# M2354 register map
File version: 1.0
Registers are 32-bit, read-write, reset 0x0 unless marked. A register's access mark holds for its fields unless they carry their own. Offsets are from the block's base; [hi:lo] are bit positions; {n}, {i} and the like mark numbered series; 'fields as' and 'values as' point back to an identical list.

## ECC_NS — CRYPTO Register Map
Base 0x50032800
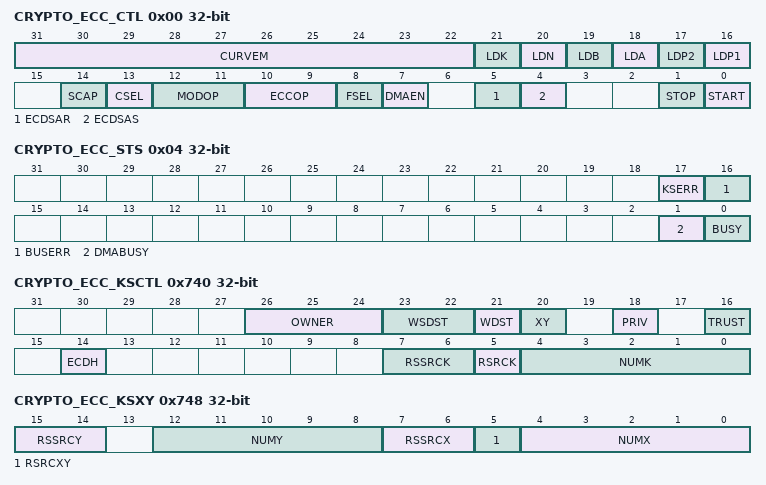
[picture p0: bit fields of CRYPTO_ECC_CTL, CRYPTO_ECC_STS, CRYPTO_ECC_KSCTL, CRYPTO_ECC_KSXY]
0x00 CRYPTO_ECC_CTL — ECC Control Register
  [31:22] CURVEM — The key length of elliptic curve.
  [21] LDK — The Control Signal of Register for SCALARK
    0=The register for SCALARK is not modified by DMA or user; 1=The register for SCALARK is modified by DMA or user
  [20] LDN — The Control Signal of Register for the Parameter CURVEN of Elliptic Curve
    0=The register for CURVEN is not modified by DMA or user; 1=The register for CURVEN is modified by DMA or user
  [19] LDB — The Control Signal of Register for the Parameter CURVEB of Elliptic Curve
    0=The register for CURVEB is not modified by DMA or user; 1=The register for CURVEB is modified by DMA or user
  [18] LDA — The Control Signal of Register for the Parameter CURVEA of Elliptic Curve
    0=The register for CURVEA is not modified by DMA or user; 1=The register for CURVEA is modified by DMA or user
  [17] LDP2 — The Control Signal of Register POINTX2 and POINTY2 for the x and Y Coordinate of the Second Point
    0=The register for POINTX2 and POINTY2 is not modified by DMA or user; 1=The register for POINTX2 and POINTY2 is modified by DMA or user
  [16] LDP1 — The Control Signal of Register POINTX1 and POINTY1 for the x and Y Coordinate of the First Point
    0=The register for POINTX1 and POINTY1 is not modified by DMA or user; 1=The register for POINTX1 and POINTY1 is modified by DMA or user
  [14] SCAP — Side-channel Attack Protection
    0=Full speed without side-channel protection; 1=Less speed with side-channel protection
  [13] CSEL — Curve Selection
    0=NIST suggested curve; 1=Montgomery curve
  [12:11] MODOP — Modulus Operation for PF
    0=Division; 1=Multiplication :; 2=Addition; 3=Subtraction :
  [10:9] ECCOP — Point Operation for BF and PF. Besides above three input data, point operations still need the parameters of elliptic curve (CURVEA, CURVEB, CURVEN and CURVEM) as shown in Figure 6.27-11.
    0=Point multiplication; 1=Modulus operation : choose by MODOP (CRYPTO_ECC_CTL[12:11]); 2=Point addition; 3=Point doubling
  [8] FSEL — Field Selection
    0=Binary Field (GF(2m )); 1=Prime Field (GF(p))
  [7] DMAEN — ECC Accelerator DMA Enable Bit. Note: Only when START and DMAEN are 1, ECC DMA engine will be active.
    0=ECC DMA engine Disabled; 1=ECC DMA engine Enabled
  [5] ECDSAR — Generate R in ECDSA Signature Generation
    0=No effect; 1=Formula for generating R
  [4] ECDSAS — Generate S in ECDSA Signature Generation
    0=No effect; 1=Formula for generating S
  [1] STOP — ECC Accelerator Stop. Note: This bit is always 0 when it is read back. Remember to clear ECC interrupt flag after stopping ECC accelerator.
    0=No effect; 1=Abort ECC accelerator and make it into idle state
  [0] START — ECC Accelerator Start. Note: This bit is always 0 when it is read back. ECC accelerator will ignore this START signal when BUSY flag is 1.
    0=No effect; 1=Start ECC accelerator. BUSY flag will be set
0x04 CRYPTO_ECC_STS ro — ECC Status Register
  [17] KSERR — ECC Engine Access Key Store Error Flag
    0=No error; 1=Access error will stop ECC engine
  [16] BUSERR — ECC DMA Access Bus Error Flag
    0=No error; 1=Bus error will stop DMA operation and ECC accelerator
  [1] DMABUSY — ECC DMA Busy Flag
    0=ECC DMA is idle or finished; 1=ECC DMA is busy
  [0] BUSY — ECC Accelerator Busy Flag. Remember to clear ECC interrupt flag after ECC accelerator finished
    0=The ECC accelerator is idle or finished; 1=The ECC accelerator is under processing and protects all registers
{0x8+4i} CRYPTO_ECC_X1_{i:02} (i=0..17) — ECC the X-coordinate Word{i} of the First Point
  [31:0] POINTX1 — ECC the X-coordinate Value of the First Point. For B-163 or K-163, POINTX1 is stored in CRYPTO_ECC_X1_00~CRYPTO_ECC_X1_05. For B-233 or K-233, POINTX1 is stored in CRYPTO_ECC_X1_00~CRYPTO_ECC_X1_07. For B-283 or K-283, POINTX1 is stored in CRYPTO_ECC_X1_00~CRYPTO_ECC_X1_08. For B-409 or K-409, POINTX1 is stored in CRYPTO_ECC_X1_00~CRYPTO_ECC_X1_12. For B-571 or K-571, POINTX1 is stored in CRYPTO_ECC_X1_00~CRYPTO_ECC_X1_17. For P-192, POINTX1 is stored in CRYPTO_ECC_X1_00~CRYPTO_ECC_X1_05. For P-224, POINTX1 is stored in CRYPTO_ECC_X1_00~CRYPTO_ECC_X1_06. For P-256, POINTX1 is stored in CRYPTO_ECC_X1_00~CRYPTO_ECC_X1_07. For P-384, POINTX1 is stored in CRYPTO_ECC_X1_00~CRYPTO_ECC_X1_11. For P-521, POINTX1 is stored in CRYPTO_ECC_X1_00~CRYPTO_ECC_X1_16
{0x50+4i} CRYPTO_ECC_Y1_{i:02} (i=0..17) — ECC the Y-coordinate Word{i} of the First Point
  [31:0] POINTY1 — ECC the Y-coordinate Value of the First Point. For B-163 or K-163, POINTY1 is stored in CRYPTO_ECC_Y1_00~CRYPTO_ECC_Y1_05. For B-233 or K-233, POINTY1 is stored in CRYPTO_ECC_Y1_00~CRYPTO_ECC_Y1_07. For B-283 or K-283, POINTY1 is stored in CRYPTO_ECC_Y1_00~CRYPTO_ECC_Y1_08. For B-409 or K-409, POINTY1 is stored in CRYPTO_ECC_Y1_00~CRYPTO_ECC_Y1_12. For B-571 or K-571, POINTY1 is stored in CRYPTO_ECC_Y1_00~CRYPTO_ECC_Y1_17. For P-192, POINTY1 is stored in CRYPTO_ECC_Y1_00~CRYPTO_ECC_Y1_05. For P-224, POINTY1 is stored in CRYPTO_ECC_Y1_00~CRYPTO_ECC_Y1_06. For P-256, POINTY1 is stored in CRYPTO_ECC_Y1_00~CRYPTO_ECC_Y1_07. For P-384, POINTY1 is stored in CRYPTO_ECC_Y1_00~CRYPTO_ECC_Y1_11. For P-521, POINTY1 is stored in CRYPTO_ECC_Y1_00~CRYPTO_ECC_Y1_16
{0x98+4i} CRYPTO_ECC_X2_{i:02} (i=0..17) — ECC the X-coordinate Word{i} of the Second Point
  [31:0] POINTX2 — ECC the X-coordinate Value of the Second Point. For B-163 or K-163, POINTX2 is stored in CRYPTO_ECC_X2_00~CRYPTO_ECC_X2_05. For B-233 or K-233, POINTX2 is stored in CRYPTO_ECC_X2_00~CRYPTO_ECC_X2_07. For B-283 or K-283, POINTX2 is stored in CRYPTO_ECC_X2_00~CRYPTO_ECC_X2_08. For B-409 or K-409, POINTX2 is stored in CRYPTO_ECC_X2_00~CRYPTO_ECC_X2_12. For B-571 or K-571, POINTX2 is stored in CRYPTO_ECC_X2_00~CRYPTO_ECC_X2_17. For P-192, POINTX2 is stored in CRYPTO_ECC_X2_00~CRYPTO_ECC_X2_05. For P-224, POINTX2 is stored in CRYPTO_ECC_X2_00~CRYPTO_ECC_X2_06. For P-256, POINTX2 is stored in CRYPTO_ECC_X2_00~CRYPTO_ECC_X2_07. For P-384, POINTX2 is stored in CRYPTO_ECC_X2_00~CRYPTO_ECC_X2_11. For P-521, POINTX2 is stored in CRYPTO_ECC_X2_00~CRYPTO_ECC_X2_16
{0xE0+4i} CRYPTO_ECC_Y2_{i:02} (i=0..17) — ECC the Y-coordinate Word{i} of the Second Point
  [31:0] POINTY2 — ECC the Y-coordinate Value of the Second Point. For B-163 or K-163, POINTY2 is stored in CRYPTO_ECC_Y2_00~CRYPTO_ECC_Y2_05. For B-233 or K-233, POINTY2 is stored in CRYPTO_ECC_Y2_00~CRYPTO_ECC_Y2_07. For B-283 or K-283, POINTY2 is stored in CRYPTO_ECC_Y2_00~CRYPTO_ECC_Y2_08. For B-409 or K-409, POINTY2 is stored in CRYPTO_ECC_Y2_00~CRYPTO_ECC_Y2_12. For B-571 or K-571, POINTY2 is stored in CRYPTO_ECC_Y2_00~CRYPTO_ECC_Y2_17. For P-192, POINTY2 is stored in CRYPTO_ECC_Y2_00~CRYPTO_ECC_Y2_05. For P-224, POINTY2 is stored in CRYPTO_ECC_Y2_00~CRYPTO_ECC_Y2_06. For P-256, POINTY2 is stored in CRYPTO_ECC_Y2_00~CRYPTO_ECC_Y2_07. For P-384, POINTY2 is stored in CRYPTO_ECC_Y2_00~CRYPTO_ECC_Y2_11. For P-521, POINTY2 is stored in CRYPTO_ECC_Y2_00~CRYPTO_ECC_Y2_16
{0x128+4i} CRYPTO_ECC_A_{i:02} (i=0..17) — ECC the Parameter CURVEA Word{i} of Elliptic Curve
  [31:0] CURVEA — ECC the Parameter CURVEA Value of Elliptic Curve. For B-163 or K-163, CURVEA is stored in CRYPTO_ECC_A_00~CRYPTO_ECC_A_05. For B-233 or K-233, CURVEA is stored in CRYPTO_ECC_A_00~CRYPTO_ECC_A_07. For B-283 or K-283, CURVEA is stored in CRYPTO_ECC_A_00~CRYPTO_ECC_A_08. For B-409 or K-409, CURVEA is stored in CRYPTO_ECC_A_00~CRYPTO_ECC_A_12. For B-571 or K-571, CURVEA is stored in CRYPTO_ECC_A_00~CRYPTO_ECC_A_17. For P-192, CURVEA is stored in CRYPTO_ECC_A_00~CRYPTO_ECC_A_05. For P-224, CURVEA is stored in CRYPTO_ECC_A_00~CRYPTO_ECC_A_06. For P-256, CURVEA is stored in CRYPTO_ECC_A_00~CRYPTO_ECC_A_07. For P-384, CURVEA is stored in CRYPTO_ECC_A_00~CRYPTO_ECC_A_11. For P-521, CURVEA is stored in CRYPTO_ECC_A_00~CRYPTO_ECC_A_16
{0x170+4i} CRYPTO_ECC_B_{i:02} (i=0..17) — ECC the Parameter CURVEB Word{i} of Elliptic Curve
  [31:0] CURVEB — ECC the Parameter CURVEB Value of Elliptic Curve. For B-163 or K-163, CURVEB is stored in CRYPTO_ECC_B_00~CRYPTO_ECC_B_05. For B-233 or K-233, CURVEB is stored in CRYPTO_ECC_B_00~CRYPTO_ECC_B_07. For B-283 or K-283, CURVEB is stored in CRYPTO_ECC_B_00~CRYPTO_ECC_B_08. For B-409 or K-409, CURVEB is stored in CRYPTO_ECC_B_00~CRYPTO_ECC_B_12. For B-521 or K-521, CURVEB is stored in CRYPTO_ECC_B_00~CRYPTO_ECC_B_17. For P-192, CURVEB is stored in CRYPTO_ECC_B_00~CRYPTO_ECC_B_05. For P-224, CURVEB is stored in CRYPTO_ECC_B_00~CRYPTO_ECC_B_06. For P-256, CURVEB is stored in CRYPTO_ECC_B_00~CRYPTO_ECC_B_07. For P-384, CURVEB is stored in CRYPTO_ECC_B_00~CRYPTO_ECC_B_11. For P-521, CURVEB is stored in CRYPTO_ECC_B_00~CRYPTO_ECC_B_16
{0x1B8+4i} CRYPTO_ECC_N_{i:02} (i=0..17) — ECC the Parameter CURVEN Word{i} of Elliptic Curve
  [31:0] CURVEN — ECC the Parameter CURVEN Value of Elliptic Curve. In GF(p), CURVEN is the prime p. In GF(2m), CURVEN is the irreducible polynomial. For B-163 or K-163, CURVEN is stored in CRYPTO_ECC_N_00~CRYPTO_ECC_N_05. For B-233 or K-233, CURVEN is stored in CRYPTO_ECC_N_00~CRYPTO_ECC_N_07. For B-283 or K-283, CURVEN is stored in CRYPTO_ECC_N_00~CRYPTO_ECC_N_08. For B-409 or K-409, CURVEN is stored in CRYPTO_ECC_N_00~CRYPTO_ECC_N_12. For B-571 or K-571, CURVEN is stored in CRYPTO_ECC_N_00~CRYPTO_ECC_N_17. For P-192, CURVEN is stored in CRYPTO_ECC_N_00~CRYPTO_ECC_N_05. For P-224, CURVEN is stored in CRYPTO_ECC_N_00~CRYPTO_ECC_N_06. For P-256, CURVEN is stored in CRYPTO_ECC_N_00~CRYPTO_ECC_N_07. For P-384, CURVEN is stored in CRYPTO_ECC_N_00~CRYPTO_ECC_N_11. For P-521, CURVEN is stored in CRYPTO_ECC_N_00~CRYPTO_ECC_N_16
{0x200+4i} CRYPTO_ECC_K_{i:02} wo (i=0..17) — ECC the Scalar SCALARK Word{i} of Point Multiplication
  [31:0] SCALARK — ECC the Scalar SCALARK Value of Point Multiplication. Because the SCALARK usually stores the private key, ECC accelerator do not allow to read the register SCALARK. For B-163 or K-163, SCALARK is stored in CRYPTO_ECC_K_00~CRYPTO_ECC_K_05. For B-233 or K-233, SCALARK is stored in CRYPTO_ECC_K_00~CRYPTO_ECC_K_07. For B-283 or K-283, SCALARK is stored in CRYPTO_ECC_K_00~CRYPTO_ECC_K_08. For B-409 or K-409, SCALARK is stored in CRYPTO_ECC_K_00~CRYPTO_ECC_K_12. For B-571 or K-571, SCALARK is stored in CRYPTO_ECC_K_00~CRYPTO_ECC_K_17. For P-192, SCALARK is stored in CRYPTO_ECC_K_00~CRYPTO_ECC_K_05. For P-224, SCALARK is stored in CRYPTO_ECC_K_00~CRYPTO_ECC_K_06. For P-256, SCALARK is stored in CRYPTO_ECC_K_00~CRYPTO_ECC_K_07. For P-384, SCALARK is stored in CRYPTO_ECC_K_00~CRYPTO_ECC_K_11. For P-521, SCALARK is stored in CRYPTO_ECC_K_00~CRYPTO_ECC_K_16
0x248 CRYPTO_ECC_SADDR — ECC DMA Source Address Register
  [31:0] SADDR — ECC DMA Source Address. The ECC accelerator supports DMA function to transfer the DATA and PARAMETER between SRAM memory space and ECC accelerator. The SADDR keeps the source address of the data buffer where the source text is stored. Based on the source address, the ECC accelerator can read the DATA and PARAMETER from SRAM memory space and do ECC operation. The start of source address should be located at word boundary. That is, bit 1 and 0 of SADDR are ignored. SADDR can be read and written. In DMA mode, software must update the CRYPTO_ECC_SADDR before triggering START.
0x24C CRYPTO_ECC_DADDR — ECC DMA Destination Address Register
  [31:0] DADDR — ECC DMA Destination Address. The ECC accelerator supports DMA function to transfer the DATA and PARAMETER between SRAM memory and ECC accelerator. The DADDR keeps the destination address of the data buffer where output data of ECC engine will be stored. Based on the destination address, the ECC accelerator can write the result data back to SRAM memory space after the ECC operation is finished. The start of destination address should be located at word boundary. That is, bit 1 and 0 of DADDR are ignored. DADDR can be read and written. In DMA mode, software must update the CRYPTO_ECC_DADDR before triggering START.
0x250 CRYPTO_ECC_STARTREG — ECC Starting Address of Updated Registers
  [31:0] STARTREG — ECC Starting Address of Updated Registers. The address of the updated registers that DMA feeds the first data or parameter to ECC engine. When ECC engine is active, ECC accelerator does not allow users to modify STARTRE.G. for example, to update input data from register CRYPTO_ECC POINTX1. Thus, the value of STARTREG is 0x808.
0x254 CRYPTO_ECC_WORDCNT — ECC DMA Word Count
  [31:0] WORDCNT — ECC DMA Word Count. The CRYPTO_ECC_WORDCNT keeps the word count of source data that is for the required input data of ECC accelerator with various operations in DMA mode. Although CRYPTO_ECC_WORDCNT is 32-bit, the maximum of word count in ECC accelerator is 144 words. CRYPTO_ECC_WORDCNT can be read and written.
0x740 CRYPTO_ECC_KSCTL wo — ECC Key Control Register
  [26:24] OWNER — Write Key Owner Selection Bits
    0=ECDH written key is only for AES use; 1=ECDH written key is only for HMAC engine use; 4=ECDH written key is only for ECC engine use; 5=ECDH written key is only for CPU engine use
  [23:22] WSDST — Write Key Store Destination
    0=ECDH written key is written to the SRAM of key store; 2=ECDH written key is written to the OTP of key store
  [21] WDST — Write Key Destination
    0=ECDH written key is in registers CRYPTO_ECC_X1 and CRYPTO_ECC_Y; 1=ECDH written key is written to key store
  [20] XY — ECDH Output Select Bit
    0=ECDH written key is from X-coordinate value; 1=ECDH written key is from Y-coordinate value
  [18] PRIV — Write Key Privilege Selection Bit
    0=Set ECDH written key as the non-privilege key; 1=Set ECDH written key as the privilege key
  [16] TRUST — Write Key Trust Selection Bit
    0=Set ECDH written key as the non-secure key; 1=Set ECDH written key as the secure key
  [14] ECDH — ECDH Control Bit
    1=Set ECC opereration is in ECDH. When this bit and RSRCK are equal to 0x1, ECC will read ECDH private key to CRYPTO_ECC_K from key store
  [7:6] RSSRCK — Read Key Store Source for Key Number K
    0=Key is read from the SRAM of key store; 2=Key is read from the OTP of key store
  [5] RSRCK — Read Key Source for Key Number K
    0=Key is read from ECC registers; 1=Key is read from key store
  [4:0] NUMK — Read Key Number K
0x744 CRYPTO_ECC_KSSTS ro — ECC Key Status Register
  [4:0] NUM — Key Number. The key number is generated by key store after ECDH.
0x748 CRYPTO_ECC_KSXY wo — ECC XY Number Register
  [15:14] RSSRCY — Read Key Store Source for Key Number Y
    values as CRYPTO_ECC_KSCTL.RSSRCK
  [12:8] NUMY — Read Key Number Y
  [7:6] RSSRCX — Read Key Store Source for Key Number X
    values as CRYPTO_ECC_KSCTL.RSSRCK
  [5] RSRCXY — Read Key Source for Key Number x and Y
    0=key is read from ECC registers; 1=key is read from key store
  [4:0] NUMX — Read Key Number X
